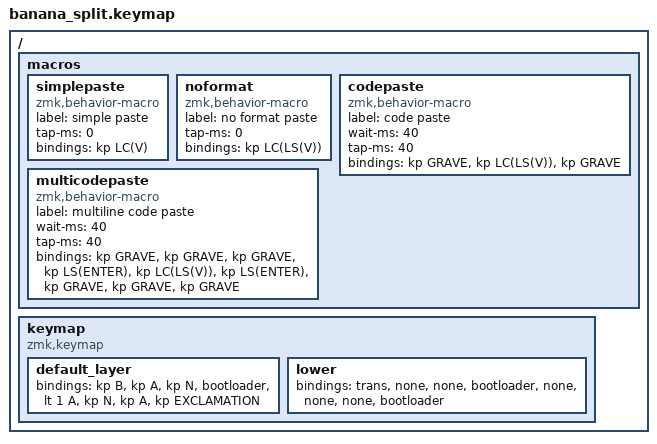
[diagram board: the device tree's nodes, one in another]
/*
 * Copyright (c) 2022 Dan Bostian
 * SPDX-License-Identifier: MIT
 */

#include <behaviors.dtsi>
#include <dt-bindings/zmk/keys.h>
#include <dt-bindings/zmk/bt.h>
#include <dt-bindings/zmk/ext_power.h>
#include <dt-bindings/zmk/outputs.h>

/ {
    macros {
    // ctrl-v
        simplepaste: simplepaste {
            label = "simple paste";
            compatible = "zmk,behavior-macro";
            #binding-cells = <0>;
            tap-ms = <0>;
            bindings
                = <&kp LC(V)>
                ;
        };
        // ctrl-shift-v
        noformat: noformat {
            label = "no format paste";
            compatible = "zmk,behavior-macro";
            #binding-cells = <0>;
            tap-ms = <0>;
            bindings
                = <&kp LC(LS(V))>
                ;
        };
       // ` + ctrl-shift-v + `
            codepaste: codepaste {
            label = "code paste";
            compatible = "zmk,behavior-macro";
            #binding-cells = <0>;
            wait-ms = <40>;
            tap-ms = <40>;
            bindings
                = <&kp GRAVE &kp LC(LS(V)) &kp GRAVE>
                ;
        };
        // ``` + shift-enter + ctrl-shift-v + shift-enter + ```
            multicodepaste: multicodepaste {
            label = "multiline code paste";
            compatible = "zmk,behavior-macro";
            #binding-cells = <0>;
            wait-ms = <40>;
            tap-ms = <40>;
            bindings
                = <&kp GRAVE &kp GRAVE &kp GRAVE &kp LS(ENTER) &kp LC(LS(V)) &kp LS(ENTER) &kp GRAVE &kp GRAVE &kp GRAVE>
                ;
        };
    };
 keymap {
        compatible =  "zmk,keymap" ;

        default_layer {
            bindings = <
                &kp B &kp A &kp N &bootloader          &lt 1 A &kp N &kp A &kp EXCLAMATION
            >; 
        };

        lower {
            bindings = <
                &trans &none &none &bootloader                                       &none &none &none &bootloader
            >; 
        };
    };
};
